# RS1xxxx register map
Vendor: Silicon Lab Inc.; Series: ARMCM4; File version: 1.2
CPU: CM4 r1p0, little endian, MPU, FPU, 6 interrupt priority bits
Registers are 32-bit, read-write, reset 0x0 unless marked. A register's access mark holds for its fields unless they carry their own. Offsets are from the block's base; [hi:lo] are bit positions; lines under a group give offsets from that group; {n}, {i} and the like mark numbered series.

## HWRNG — Random numbers generated are 16-bit random numbers and are generated using either the True random number generator or the Pseudo random number generator.
Base 0x45090000
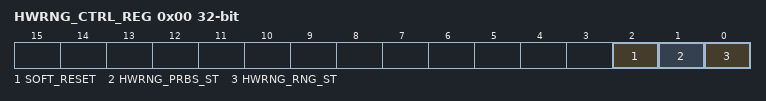
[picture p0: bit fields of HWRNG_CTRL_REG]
0x00 HWRNG_CTRL_REG — Random Number Generator Control Register
  [2] SOFT_RESET — This bit is used to start the pseudo random number generation
    1=Enable (Reset the scrambled data); 0=Disable (Not resetted)
  [1] HWRNG_PRBS_ST — This bit is used to start the pseudo random number generation
    1=Enables pseudo random number generation; 0=Disables pseudo random number generation
  [0] HWRNG_RNG_ST — This bit is used to start the true number generation.
    1=Enables true random number generation; 0=Disables true random number generation
0x04 HWRNG_RAND_NUM_REG ro — Hardware Random Number Register
  [31:0] HWRNG_RAND_NUM — Generated random number can be read from this register.

## ULP_TIMERS — TIMER can be used to generate various timing events for the software
Base 0x24042000
{0x0+8i} MATCH_CTRLn[{i}] (i=0..3) group — MATCH Control registers (0-3)
  0x00 MCUULP_TMR_n__MATCH reset 0xFFFF (reset mask 0xFFFF) — Timer Match Register
    [31:0] TMR_MATCH — This bits are used to program the lower significant 16-bits of timer time out value in millisecond or number of system clocks
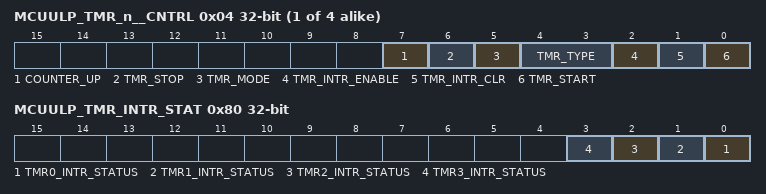
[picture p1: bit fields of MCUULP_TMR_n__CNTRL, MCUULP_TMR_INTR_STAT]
  0x04 MCUULP_TMR_n__CNTRL — Timer Control Register
    [7] COUNTER_UP — For reading/tracking counter in up counting this bit has to be set
    [6] TMR_STOP wo — This Bit are Used to stop the timer
      1=None (Stops the timer)
    [5] TMR_MODE — This Bit are Used to select the mode working of timer
      1=Enable (Periodic timer); 0=Disable (One shot timer)
    [4:3] TMR_TYPE — This Bit are Used to select the type of timer
      2=256_MICRO_SECOND (256 Micro second mode); 1=ONE_MICRO_SECOND (1 Micro second mode); 0=COUNT_DOWN_TIMER
    [2] TMR_INTR_ENABLE — This Bit are Used to enable the time out interrupt
      1=Enable (Interrupt enable); 0=Disable (Interrupt disable)
    [1] TMR_INTR_CLR wo — This Bit are Used to clear the timer
      1=Clear_Interrupt
    [0] TMR_START wo — This Bit are Used to start the timer timer gets reset upon setting this bit
      1=None (Timer start)
0x80 MCUULP_TMR_INTR_STAT — Timer Status Register
  [all] fields
    1=Interrupt_Present; 0=Interrupt_Absent (No Interrupt present)
  [n] TMR{n}_INTR_STATUS (n=0..3) — This bit indicates status of the interrupt generated by timer {n}
0x84 MCUULP_TMR_US_PERIOD_INT reset 0xFFFF — Timer micro second period Integral Part Register
  [15:0] TMR_US_PERIOD_INT — This bits are used to program the integer part of number of clock cycles per microseconds of the system clock used
0x88 MCUULP_TMR_US_PERIOD_FRAC reset 0xFF — Timer microsecond period Fractional Part Register
  [7:0] TMR_US_PERIOD_FRAC — This bits are used to program the fractional part of number of clock cycles per microseconds of the system clock used
0x8C MCUULP_TMR_MS_PERIOD_INT reset 0xFFFF — Timer 256 microsecond period Integral Part Register
  [15:0] TMR_MS_PERIOD_INT — This bits are used to program the integer part of number of clock cycles per 256 microseconds of the system clock used
0x90 MCUULP_TMR_MS_PERIOD_FRAC reset 0xFF — Timer 256 microsecond period Fractional Part Register
  [7:0] TMR_MS_PERIOD_FRAC — This bits are used to program the fractional part of number of clock cycles per 256 microseconds of the system clock used
0x9C MCUULP_TMR_ACTIVE_STATUS ro reset not defined — Timer Active Status Register
  [3:0] TIMER_ACTIVE — Timer active status for each timer. LSB bit specifies the status for 0th timer and so on.
    1=Timer_Active (Interrupt present); 0=Timer_Inative (No Interrupt present)
